# ATmega406 register map
Vendor: Atmel; File version: 1.0
CPU: other r0p0, little endian, no MPU, no FPU, 4 interrupt priority bits
Registers are 8-bit, read-write, reset 0x0 unless marked. A register's access mark holds for its fields unless they carry their own. Offsets are from the block's base; lines under a group give offsets from that group; [hi:lo] are bit positions; {n}, {i} and the like mark numbered series; 'fields as' and 'values as' point back to an identical list; <NAME> marks a mode.

## Memory map
0x00000000 FUSE size 0x2 — Fuses
0x00000000 LOCKBIT size 0x1 — Lockbits
0x00000020 PORTA size 0x3 — I/O Port
0x00000023 PORTB size 0x3 — I/O Port
0x00000028 PORTC size 0x1 — I/O Port
0x00000029 PORTD size 0x3 — I/O Port
0x00000035 TC0 blocks up to offset 0x3A — Timer/Counter, 8-bit
0x00000036 TC1 blocks up to offset 0x54 — Timer/Counter, 16-bit
0x0000003B EXINT blocks up to offset 0x32 — External Interrupts
0x0000003E CPU blocks up to offset 0x83 — CPU Registers
0x0000003F EEPROM size 0x4
0x00000057 BOOT_LOAD size 0x1 — Bootloader
0x00000060 WDT size 0x1 — Watchdog Timer
0x00000062 WAKEUP_TIMER size 0x1
0x00000078 ADC blocks up to offset 0x5 — Analog-to-Digital Converter
0x000000B8 TWI size 0x7 — Two Wire Serial Interface
0x000000D0 BANDGAP size 0x2
0x000000E0 COULOMB_COUNTER size 0xA
0x000000F0 FET size 0x1 — FET Control
0x000000F1 CELL_BALANCING size 0x1
0x000000F2 BATTERY_PROTECTION size 0x7

## Interrupts
0 RESET (CPU) — External Pin, Power-on Reset, Brown-out Reset and Watchdog Reset
1 BPINT (CPU) — Battery Protection Interrupt
2 INT0 (CPU) — External Interrupt Request 0
3 INT1 (CPU) — External Interrupt Request 1
4 INT2 (CPU) — External Interrupt Request 2
5 INT3 (CPU) — External Interrupt Request 3
6 PCINT0 (CPU) — Pin Change Interrupt 0
7 PCINT1 (CPU) — Pin Change Interrupt 1
8 WDT (CPU) — Watchdog Timeout Interrupt
9 WAKE_UP (CPU) — Wakeup timer overflow
10 TIM1_COMP (CPU) — Timer/Counter 1 Compare Match
11 TIM1_OVF (CPU) — Timer/Counter 1 Overflow
12 TIM0_COMPA (CPU) — Timer/Counter0 Compare A Match
13 TIM0_COMPB (CPU) — Timer/Counter0 Compare B Match
14 TIM0_OVF (CPU) — Timer/Counter0 Overflow
15 TWI_BUS_CD (CPU) — Two-Wire Bus Connect/Disconnect
16 TWI (CPU) — Two-Wire Serial Interface
17 VADC (CPU) — Voltage ADC Conversion Complete
18 CCADC_CONV (CPU) — Coulomb Counter ADC Conversion Complete
19 CCADC_REG_CUR (CPU) — Coloumb Counter ADC Regular Current
20 CCADC_ACC (CPU) — Coloumb Counter ADC Accumulator
21 EE_READY (CPU) — EEPROM Ready
22 SPM_READY (CPU) — Store Program Memory Ready

## ADC — Analog-to-Digital Converter
Base 0x00000078
0x00 VADC 16-bit (reset mask 0xFF) — VADC Data Register Bytes
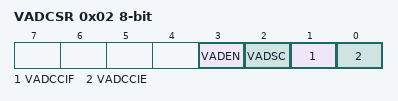
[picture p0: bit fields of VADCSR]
0x02 VADCSR — The VADC Control and Status register
  [3] VADEN — VADC Enable
  [2] VADSC — VADC Satrt Conversion
  [1] VADCCIF — VADC Conversion Complete Interrupt Flag
  [0] VADCCIE — VADC Conversion Complete Interrupt Enable
0x04 VADMUX — The VADC multiplexer Selection Register
  [3:0] VADMUX — Analog Channel and Gain Selection Bits

## BANDGAP
Base 0x000000D0
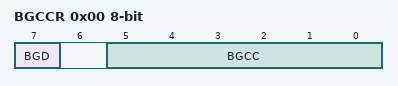
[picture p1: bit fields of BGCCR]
0x00 BGCCR — Bandgap Calibration Register
  [7] BGD — Setting the BGD bit to one will disable the bandgap voltage reference. This bit must be cleared before enabling CC-ADC or V-ADC, and must remain unset while either ADC is enabled.
  [5:0] BGCC — BG Calibration of PTAT Current Bits
0x01 BGCRR — Bandgap Calibration of Resistor Ladder

## BATTERY_PROTECTION
Base 0x000000F2
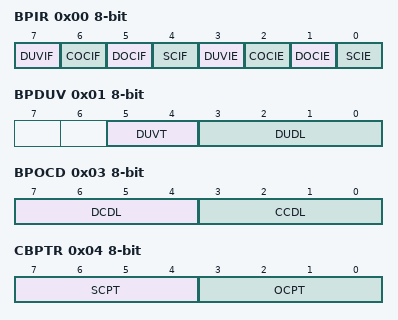
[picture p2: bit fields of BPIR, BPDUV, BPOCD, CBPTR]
0x00 BPIR — Battery Protection Interrupt Register
  [7] DUVIF — Deep Under-voltage Early Warning Interrupt Flag
  [6] COCIF — Charge Over-current Protection Activated Interrupt Flag
  [5] DOCIF
  [4] SCIF
  [3] DUVIE — Deep Under-voltage Early Warning Interrupt Enable
  [2] COCIE
  [1] DOCIE
  [0] SCIE
0x01 BPDUV — Battery Protection Deep Under Voltage Register
  [5:4] DUVT
    0=750ms; 1=1000ms; 2=1250ms; 3=1500ms
  [3:0] DUDL
    0=4.71V; 1=5.03V; 2=5.34V; 3=5.66V; 4=5.97V; 5=6.29V; 6=6.60V; 7=6.91V; 8=7.23V; 9=7.54V; 10=7.86V; 11=8.17V; 12=8.49V; 13=8.80V; 14=9.11V; 15=9.43V
0x02 BPSCD — Battery Protection Short-Circuit Detection Level Register
  [3:0] SCDL
    0=0.100V; 1=0.110V; 2=0.120V; 3=0.130V; 4=0.140V; 5=0.160V; 6=0.180V; 7=0.200V; 8=0.220V; 9=0.240V; 10=0.260V; 11=0.280V; 12=0.320V; 13=0.360V; 14=0.400V; 15=0.440V
0x03 BPOCD — Battery Protection OverCurrent Detection Level Register
  [7:4] DCDL
    0=0.050V; 1=0.055V; 2=0.060V; 3=0.065V; 4=0.070V; 5=0.080V; 6=0.090V; 7=0.100V; 8=0.110V; 9=0.120V; 10=0.130V; 11=0.140V; 12=0.160V; 13=0.180V; 14=0.200V; 15=0.220V
  [3:0] CCDL
    values as DCDL
0x04 CBPTR — Current Battery Protection Timing Register
  [7:4] SCPT
    0=61 us; 1=122 us; 2=183 us; 3=244 us; 4=305 us; 5=366 us; 6=427 us; 7=488 us; 8=610 us; 9=732 us; 10=854 us; 11=976 us; 12=1098 us; 13=1220 us; 14=1342 us; 15=1464 us
  [3:0] OCPT
    0=1 ms; 1=2 ms; 2=4 ms; 3=6 ms; 4=8 ms; 5=10 ms; 6=12 ms; 7=14 ms; 8=16 ms; 9=18 ms; 10=20 ms; 11=22 ms; 12=24 ms; 13=26 ms; 14=28 ms; 15=30 ms
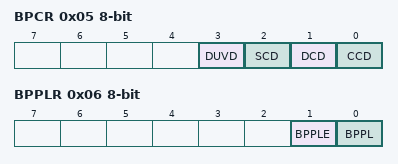
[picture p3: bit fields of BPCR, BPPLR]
0x05 BPCR — Battery Protection Control Register
  [3] DUVD, [2] SCD, [1] DCD, [0] CCD
0x06 BPPLR — Battery Protection Parameter Lock Register
  [1] BPPLE — Battery Protection Parameter Lock Enable
  [0] BPPL — Battery Protection Parameter Lock
